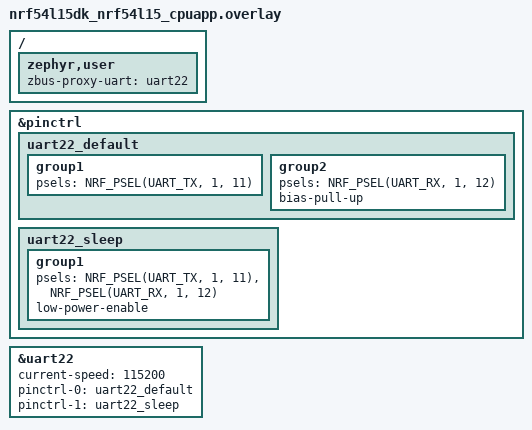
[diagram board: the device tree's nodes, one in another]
/*
 * Copyright (c) 2026 Nordic Semiconductor ASA
 *
 * SPDX-License-Identifier: Apache-2.0
 */

/ {
	zephyr,user {
		zbus-proxy-uart = <&uart22>;
	};
};

&pinctrl {
	uart22_default: uart22_default {
		group1 {
			psels = <NRF_PSEL(UART_TX, 1, 11)>;
		};

		group2 {
			psels = <NRF_PSEL(UART_RX, 1, 12)>;
			bias-pull-up;
		};
	};

	uart22_sleep: uart22_sleep {
		group1 {
			psels = <NRF_PSEL(UART_TX, 1, 11)>,
				<NRF_PSEL(UART_RX, 1, 12)>;
			low-power-enable;
		};
	};
};

&uart22 {
	status = "okay";
	current-speed = <115200>;
	/delete-property/ hw-flow-control;
	pinctrl-0 = <&uart22_default>;
	pinctrl-1 = <&uart22_sleep>;
	pinctrl-names = "default", "sleep";
};
